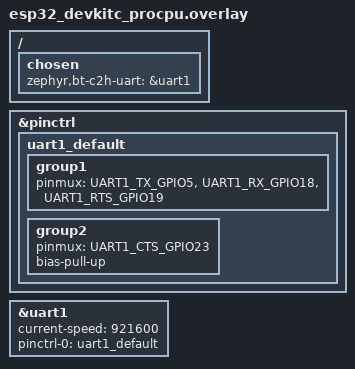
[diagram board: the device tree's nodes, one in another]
/*
 * Copyright (c) 2021 Espressif Systems (Shanghai) Co., Ltd.
 *
 * SPDX-License-Identifier: Apache-2.0
 */

/ {
	chosen {
		zephyr,bt-c2h-uart = &uart1;
	};
};

&pinctrl {

	uart1_default: uart1_default {
		group1 {
			pinmux = <UART1_TX_GPIO5>,
				 <UART1_RX_GPIO18>,
				 <UART1_RTS_GPIO19>;
		};
		group2 {
			pinmux = <UART1_CTS_GPIO23>;
			bias-pull-up;
		};
	};
};

&uart1 {
	status = "okay";
	current-speed = <921600>;
	pinctrl-0 = <&uart1_default>;
	pinctrl-names = "default";
};
